# RN821X_RN721X_SOC_V2 register map
File version: v1.0.7
CPU: CM0 r0p0, little endian, no MPU, no FPU, 3 interrupt priority bits
Registers are 32-bit, read-write, reset 0x0 unless marked. A register's access mark holds for its fields unless they carry their own. Offsets are from the block's base; [hi:lo] are bit positions.

## SPI0 — synchronous peripheral interface
Base 0x40020000
Same registers: SPI1 0x40050000, SPI2 0x40054000, SPI3 0x40058000
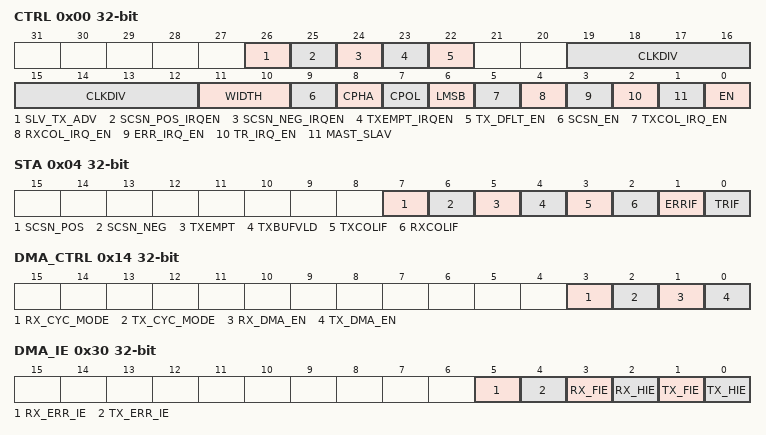
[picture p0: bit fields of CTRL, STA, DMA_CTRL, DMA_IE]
0x00 CTRL — SPI control register
  [26] SLV_TX_ADV — SPI slave high speed mode enable
    0=LM (select SPI as slave low speed mode if device configrate as slave); 1=HM (select SPI as slave high speed mode if device configrate as slave)
  [25] SCSN_POS_IRQEN — CSN POS interrupt
  [24] SCSN_NEG_IRQEN — CSN NEG interrupt
  [23] TXEMPT_IRQEN — transmit empty interrupt
  [22] TX_DFLT_EN — transmit data when TX buffer empty
    1=DFLT (transmit SPI_TXDFLT reg data when transmit buffer empty); 0=LAST (transmit last time reg data of SPI_TXDATA when transmit buffer empty)
  [19:12] CLKDIV — clock divisor for SCK.frequency of SCK is (frequency of system clock)/(2*(CLKDIV+1))
  [11:10] WIDTH — data width selection
    0=8BIT (select data width as 8 bit); 1=16BIT (select data width as 16 bit); 2=32BIT (select data width as 32 bit)
  [9] SCSN_EN — SCSN error detection enable.applicable in master mode
  [8] CPHA — clock phase selection
    0=SAMP (leading edge sampling data, trailing edge build data); 1=BUILD (leading edge build data, trailing edge sampling data)
  [7] CPOL — clock polarity selection
    0=EL (select low level for 'SCK' empty status); 1=EH (select high level for 'SCK' empty status)
  [6] LMSB — LSB or MSB selection
    0=MSB (MSB transmitted first); 1=LSB (LSB transmitted first)
  [5] TXCOL_IRQ_EN — transmit data collision interrupt enable
  [4] RXCOL_IRQ_EN — receive data collision interrupt enable
  [3] ERR_IRQ_EN — SCSN error interrupt enable
  [2] TR_IRQ_EN — transmit interrupt enable
  [1] MAST_SLAV — master slave selection
    1=M (select as master device); 0=S (select as slave device)
  [0] EN — module enable
0x04 STA — SPI status register
  [7] SCSN_POS — CSN negedge flag
  [6] SCSN_NEG — CSN posedge flag
  [5] TXEMPT — transmit buffer empty conflict flag (buffer empty but need to transmit)
  [4] TXBUFVLD — transmit buffer not empty flag
  [3] TXCOLIF write-1-clears — transmit data overflow interrupt flag
  [2] RXCOLIF write-1-clears — receive data overflow interrupt flag
  [1] ERRIF write-1-clears — SCSN error interrupt flag
  [0] TRIF write-1-clears — transmit interrupt flag
0x08 TX — SPI transmit data register
  [31:0] TX — transmit data bits
0x0C RX ro — SPI receive data register
  [31:0] RX — receive data bits
0x10 TXDFLT — SPI tx default data register
  [31:0] TXDFLT — transmit default data bits
0x14 DMA_CTRL — SPI DMA control register
  [3] RX_CYC_MODE — periodic receive enable bit
  [2] TX_CYC_MODE — periodic transmit enable bit
  [1] RX_DMA_EN — receive DMA enable bit
  [0] TX_DMA_EN — transmit DMA enable bit
0x18 DMA_TBADR — SPI DMA TX base address register
  [16:0] DMA_TBADR — DMA transmit begin addr configuration bits
0x1C DMA_RBADR — SPI DMA RX base address register
  [16:0] DMA_RBADR — DMA receive begin addr configuration bits
0x20 DMA_TLEN — SPI DMA TX length register
  [16:0] DMA_TLEN — DMA transmit length configuration bits
0x24 DMA_RLEN — SPI DMA RX length register
  [16:0] DMA_RLEN — DMA receive length configuration bits
0x28 DMA_TADR ro — SPI DMA TX current address register
  [16:0] DMA_TADR — current transmit DMA addr bits
0x2C DMA_RADR ro — SPI DMA RX current address register
  [16:0] DMA_RADR — current receive DMA addr bits
0x30 DMA_IE — SPI DMA interrupt enable register
  [5] RX_ERR_IE — DMA receive error(data recover) interrupt enable bit
  [4] TX_ERR_IE — DMA transmit error interrupt enable bit
  [3] RX_FIE — DMA receive full interrupt enable bit
  [2] RX_HIE — DMA transmit half-full interrupt enable bit
  [1] TX_FIE — DMA receive full interrupt enable bit
  [0] TX_HIE — DMA transmit half-full interrupt enable bit
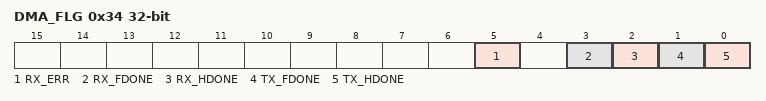
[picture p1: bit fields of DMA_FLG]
0x34 DMA_FLG — SPI DMA interrupt flag register
  [5] RX_ERR write-1-clears — DMA receive error interrupt flag
  [3] RX_FDONE write-1-clears — DMA receive full interrupt flag
  [2] RX_HDONE write-1-clears — DMA receive half-full interrupt flag
  [1] TX_FDONE write-1-clears — DMA transmit full interrupt flag
  [0] TX_HDONE write-1-clears — DMA transmit half-full interrupt flag
